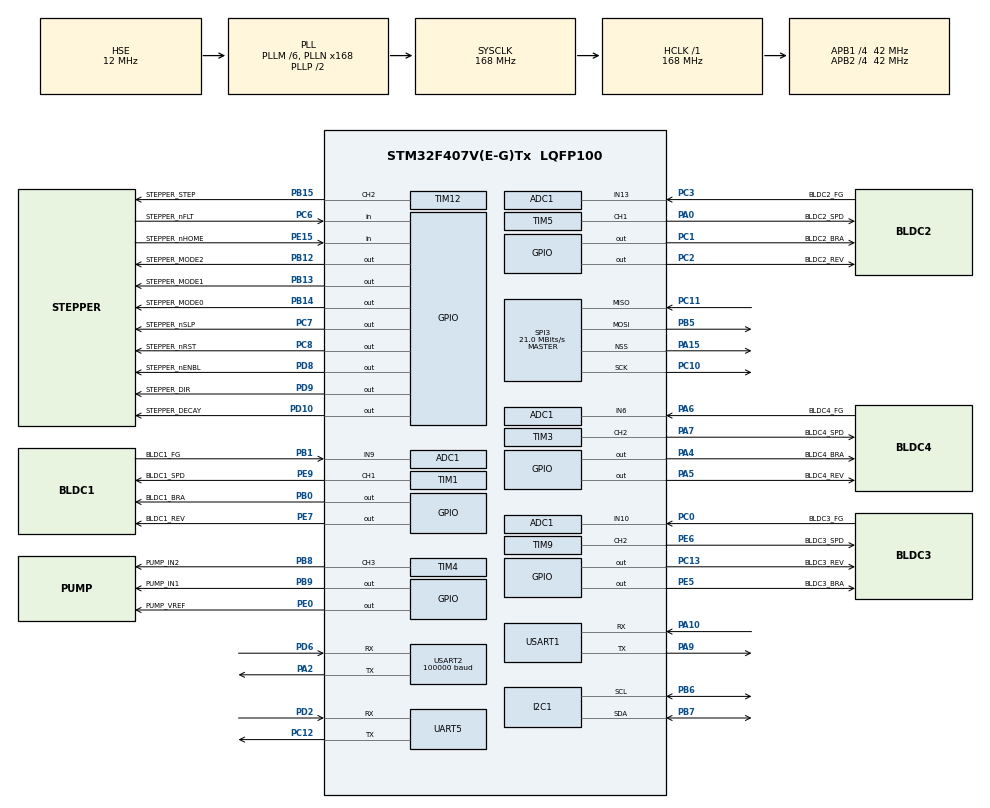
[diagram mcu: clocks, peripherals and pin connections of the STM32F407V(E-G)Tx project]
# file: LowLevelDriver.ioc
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ADC1.Channel-1\#ChannelRegularConversion=ADC_CHANNEL_9
ADC1.Channel-2\#ChannelRegularConversion=ADC_CHANNEL_6
ADC1.Channel-3\#ChannelRegularConversion=ADC_CHANNEL_10
ADC1.Channel-4\#ChannelRegularConversion=ADC_CHANNEL_13
ADC1.ClockPrescaler=ADC_CLOCK_SYNC_PCLK_DIV6
ADC1.ContinuousConvMode=ENABLE
ADC1.DMAContinuousRequests=ENABLE
ADC1.EOCSelection=ADC_EOC_SEQ_CONV
ADC1.NbrOfConversion=4
ADC1.NbrOfConversionFlag=1
ADC1.Rank-1\#ChannelRegularConversion=1
ADC1.Rank-2\#ChannelRegularConversion=2
ADC1.Rank-3\#ChannelRegularConversion=3
ADC1.Rank-4\#ChannelRegularConversion=4
ADC1.SamplingTime-1\#ChannelRegularConversion=ADC_SAMPLETIME_56CYCLES
ADC1.SamplingTime-2\#ChannelRegularConversion=ADC_SAMPLETIME_56CYCLES
ADC1.SamplingTime-3\#ChannelRegularConversion=ADC_SAMPLETIME_56CYCLES
ADC1.SamplingTime-4\#ChannelRegularConversion=ADC_SAMPLETIME_56CYCLES
ADC1.ScanConvMode=ENABLE
ADC1.master=1
Dma.ADC1.0.Direction=DMA_PERIPH_TO_MEMORY
Dma.ADC1.0.FIFOMode=DMA_FIFOMODE_DISABLE
Dma.ADC1.0.Instance=DMA2_Stream0
Dma.ADC1.0.MemDataAlignment=DMA_MDATAALIGN_HALFWORD
Dma.ADC1.0.MemInc=DMA_MINC_ENABLE
Dma.ADC1.0.Mode=DMA_CIRCULAR
Dma.ADC1.0.PeriphDataAlignment=DMA_PDATAALIGN_HALFWORD
Dma.ADC1.0.PeriphInc=DMA_PINC_DISABLE
Dma.ADC1.0.Priority=DMA_PRIORITY_LOW
Dma.Request0=ADC1
Dma.Request1=USART2_RX
Dma.USART2_RX.1.Direction=DMA_PERIPH_TO_MEMORY
Dma.USART2_RX.1.FIFOMode=DMA_FIFOMODE_DISABLE
Dma.USART2_RX.1.Instance=DMA1_Stream5
Dma.USART2_RX.1.MemDataAlignment=DMA_MDATAALIGN_BYTE
Dma.USART2_RX.1.MemInc=DMA_MINC_ENABLE
Dma.USART2_RX.1.Mode=DMA_NORMAL
Dma.USART2_RX.1.PeriphDataAlignment=DMA_PDATAALIGN_BYTE
Dma.USART2_RX.1.PeriphInc=DMA_PINC_DISABLE
Dma.USART2_RX.1.Priority=DMA_PRIORITY_LOW
FREERTOS.Tasks01=defaultTask,0,128,StartDefaultTask,Default,NULL,Dynamic,NULL,NULL
FREERTOS.configENABLE_FPU=1
Mcu.Family=STM32F4
Mcu.Name=STM32F407V(E-G)Tx
Mcu.Package=LQFP100
NVIC.DMA1_Stream5_IRQn=true\:5\:0\:false\:false\:true\:true\:false\:true\:true
NVIC.DMA2_Stream0_IRQn=true\:5\:0\:false\:false\:true\:true\:false\:true\:true
NVIC.PriorityGroup=NVIC_PRIORITYGROUP_4
NVIC.TIM6_DAC_IRQn=true\:15\:0\:false\:false\:true\:false\:false\:true\:true
NVIC.TimeBase=TIM6_DAC_IRQn
NVIC.TimeBaseIP=TIM6
PA0-WKUP.GPIO_Label=BLDC2_SPD
PA0-WKUP.Signal=S_TIM5_CH1
PA10.Mode=Asynchronous
PA10.Signal=USART1_RX
PA13.Mode=Serial_Wire
PA13.Signal=SYS_JTMS-SWDIO
PA14.Mode=Serial_Wire
PA14.Signal=SYS_JTCK-SWCLK
PA15.Mode=NSS_Signal_Hard_Output
PA15.Signal=SPI3_NSS
PA2.Mode=Asynchronous
PA2.Signal=USART2_TX
PA4.GPIO_Label=BLDC4_BRA
PA4.Signal=GPIO_Output
PA5.GPIO_Label=BLDC4_REV
PA5.Signal=GPIO_Output
PA6.GPIO_Label=BLDC4_FG
PA6.Signal=ADCx_IN6
PA7.GPIO_Label=BLDC4_SPD
PA7.Signal=S_TIM3_CH2
PA9.Mode=Asynchronous
PA9.Signal=USART1_TX
PB0.GPIO_Label=BLDC1_BRA
PB0.Signal=GPIO_Output
PB1.GPIO_Label=BLDC1_FG
PB1.Signal=ADCx_IN9
PB12.GPIO_Label=STEPPER_MODE2
PB12.Signal=GPIO_Output
PB13.GPIO_Label=STEPPER_MODE1
PB13.Signal=GPIO_Output
PB14.GPIO_Label=STEPPER_MODE0
PB14.Signal=GPIO_Output
PB15.GPIO_Label=STEPPER_STEP
PB15.Signal=S_TIM12_CH2
PB5.Mode=Full_Duplex_Master
PB5.Signal=SPI3_MOSI
PB6.Mode=I2C
PB6.Signal=I2C1_SCL
PB7.Mode=I2C
PB7.Signal=I2C1_SDA
PB8.GPIO_Label=PUMP_IN2
PB8.Signal=S_TIM4_CH3
PB9.GPIO_Label=PUMP_IN1
PB9.PinState=GPIO_PIN_SET
PB9.Signal=GPIO_Output
PC0.GPIO_Label=BLDC3_FG
PC0.Signal=ADCx_IN10
PC1.GPIO_Label=BLDC2_BRA
PC1.Signal=GPIO_Output
PC10.Mode=Full_Duplex_Master
PC10.Signal=SPI3_SCK
PC11.Mode=Full_Duplex_Master
PC11.Signal=SPI3_MISO
PC12.Mode=Asynchronous
PC12.Signal=UART5_TX
PC13-ANTI_TAMP.GPIO_Label=BLDC3_REV
PC13-ANTI_TAMP.Signal=GPIO_Output
PC2.GPIO_Label=BLDC2_REV
PC2.Signal=GPIO_Output
PC3.GPIO_Label=BLDC2_FG
PC3.Signal=ADCx_IN13
PC6.GPIO_Label=STEPPER_nFLT
PC6.GPIO_PuPd=GPIO_PULLUP
PC6.Signal=GPIO_Input
PC7.GPIO_Label=STEPPER_nSLP
PC7.PinState=GPIO_PIN_SET
PC7.Signal=GPIO_Output
PC8.GPIO_Label=STEPPER_nRST
PC8.Signal=GPIO_Output
PD10.GPIO_Label=STEPPER_DECAY
PD10.Signal=GPIO_Output
PD2.Mode=Asynchronous
PD2.Signal=UART5_RX
PD6.Mode=Asynchronous
PD6.Signal=USART2_RX
PD8.GPIO_Label=STEPPER_nENBL
PD8.Signal=GPIO_Output
PD9.GPIO_Label=STEPPER_DIR
PD9.Signal=GPIO_Output
PE0.GPIO_Label=PUMP_VREF
PE0.PinState=GPIO_PIN_SET
PE0.Signal=GPIO_Output
PE15.GPIO_Label=STEPPER_nHOME
PE15.GPIO_PuPd=GPIO_PULLUP
PE15.Signal=GPIO_Input
PE5.GPIO_Label=BLDC3_BRA
PE5.Signal=GPIO_Output
PE6.GPIO_Label=BLDC3_SPD
PE6.Signal=S_TIM9_CH2
PE7.GPIO_Label=BLDC1_REV
PE7.Signal=GPIO_Output
PE9.GPIO_Label=BLDC1_SPD
PE9.Signal=S_TIM1_CH1
PH0-OSC_IN.Mode=HSE-External-Oscillator
PH0-OSC_IN.Signal=RCC_OSC_IN
PH1-OSC_OUT.Mode=HSE-External-Oscillator
PH1-OSC_OUT.Signal=RCC_OSC_OUT
ProjectManager.HeapSize=0x200
ProjectManager.StackSize=0x400
ProjectManager.TargetToolchain=MDK-ARM V5.32
RCC.48MHZClocksFreq_Value=48000000
RCC.AHBFreq_Value=168000000
RCC.APB1CLKDivider=RCC_HCLK_DIV4
RCC.APB1Freq_Value=42000000
RCC.APB1TimFreq_Value=84000000
RCC.APB2CLKDivider=RCC_HCLK_DIV4
RCC.APB2Freq_Value=42000000
RCC.APB2TimFreq_Value=84000000
RCC.CortexFreq_Value=168000000
RCC.HCLKFreq_Value=168000000
RCC.HSE_VALUE=12000000
RCC.HSI_VALUE=16000000
RCC.LSE_VALUE=32768
RCC.PLLM=6
RCC.PLLN=168
RCC.PLLQ=7
RCC.PLLSourceVirtual=RCC_PLLSOURCE_HSE
RCC.SYSCLKFreq_VALUE=168000000
RCC.SYSCLKSource=RCC_SYSCLKSOURCE_PLLCLK
RCC.VCOOutputFreq_Value=336000000
SH.ADCx_IN10.0=ADC1_IN10,IN10
SH.ADCx_IN13.0=ADC1_IN13,IN13
SH.ADCx_IN6.0=ADC1_IN6,IN6
SH.ADCx_IN9.0=ADC1_IN9,IN9
SH.S_TIM12_CH2.0=TIM12_CH2,PWM Generation2 CH2
SH.S_TIM1_CH1.0=TIM1_CH1,PWM Generation1 CH1
SH.S_TIM3_CH2.0=TIM3_CH2,PWM Generation2 CH2
SH.S_TIM4_CH3.0=TIM4_CH3,PWM Generation3 CH3
SH.S_TIM5_CH1.0=TIM5_CH1,PWM Generation1 CH1
SH.S_TIM9_CH2.0=TIM9_CH2,PWM Generation2 CH2
SPI3.BaudRatePrescaler=SPI_BAUDRATEPRESCALER_2
SPI3.CalculateBaudRate=21.0 MBits/s
SPI3.Direction=SPI_DIRECTION_2LINES
SPI3.Mode=SPI_MODE_MASTER
SPI3.VirtualNSS=VM_NSSHARD
SPI3.VirtualType=VM_MASTER
TIM1.Channel-PWM\ Generation1\ CH1=TIM_CHANNEL_1
TIM1.OCPolarity_1=TIM_OCPOLARITY_LOW
TIM1.Period=1000 - 1
TIM1.Prescaler=4 - 1
TIM12.Channel-PWM\ Generation2\ CH2=TIM_CHANNEL_2
TIM12.Period=400 - 1
TIM12.Prescaler=21 - 1
TIM12.Pulse-PWM\ Generation2\ CH2=200
TIM3.Channel-PWM\ Generation2\ CH2=TIM_CHANNEL_2
TIM3.OCPolarity_2=TIM_OCPOLARITY_LOW
TIM3.Period=1000 - 1
TIM3.Prescaler=4 - 1
TIM4.Channel-PWM\ Generation3\ CH3=TIM_CHANNEL_3
TIM4.OCPolarity_3=TIM_OCPOLARITY_LOW
TIM4.Period=1000 - 1
TIM4.Prescaler=4 - 1
TIM5.Channel-PWM\ Generation1\ CH1=TIM_CHANNEL_1
TIM5.OCPolarity_1=TIM_OCPOLARITY_LOW
TIM5.Period=1000 - 1
TIM5.Prescaler=4 - 1
TIM9.Channel-PWM\ Generation2\ CH2=TIM_CHANNEL_2
TIM9.OCPolarity_2=TIM_OCPOLARITY_LOW
TIM9.Period=1000 - 1
TIM9.Prescaler=4 - 1
UART5.VirtualMode=Asynchronous
USART1.VirtualMode=VM_ASYNC
USART2.BaudRate=100000
USART2.Mode=MODE_RX
USART2.Parity=PARITY_EVEN
USART2.StopBits=STOPBITS_2
USART2.VirtualMode=VM_ASYNC
USART2.WordLength=WORDLENGTH_9B
VP_FREERTOS_VS_CMSIS_V1.Mode=CMSIS_V1
VP_RNG_VS_RNG.Mode=RNG_Activate
VP_SYS_VS_tim6.Mode=TIM6
VP_TIM12_VS_ClockSourceINT.Mode=Internal
VP_TIM1_VS_ClockSourceINT.Mode=Internal
VP_TIM3_VS_ClockSourceINT.Mode=Internal
VP_TIM4_VS_ClockSourceINT.Mode=Internal
VP_TIM5_VS_ClockSourceINT.Mode=Internal
VP_TIM9_VS_ClockSourceINT.Mode=Internal
board=custom

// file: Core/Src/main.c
/* USER CODE BEGIN Header */
/**
  ******************************************************************************
  * @file           : main.c
  * @brief          : Main program body
  ******************************************************************************
  * @attention
  *
  * Copyright (c) 2025 STMicroelectronics.
  * All rights reserved.
  *
  * This software is licensed under terms that can be found in the LICENSE file
  * in the root directory of this software component.
  * If no LICENSE file comes with this software, it is provided AS-IS.
  *
  ******************************************************************************
  */
/* USER CODE END Header */
#include "main.h"
#include "cmsis_os.h"
#include "adc.h"
#include "dma.h"
#include "i2c.h"
#include "rng.h"
#include "spi.h"
#include "tim.h"
#include "usart.h"
#include "gpio.h"

void SystemClock_Config(void);
void MX_FREERTOS_Init(void);

int main(void)
{

  /* MCU Configuration--------------------------------------------------------*/

  /* Reset of all peripherals, Initializes the Flash interface and the Systick. */
  HAL_Init();

  /* Configure the system clock */
  SystemClock_Config();

  /* Initialize all configured peripherals */
  MX_GPIO_Init();
  MX_DMA_Init();
  MX_ADC1_Init();
  MX_TIM1_Init();
  MX_TIM3_Init();
  MX_TIM4_Init();
  MX_TIM5_Init();
  MX_TIM9_Init();
  MX_TIM12_Init();
  MX_I2C1_Init();
  MX_RNG_Init();
  MX_SPI3_Init();
  MX_UART5_Init();
  MX_USART1_UART_Init();
  MX_USART2_UART_Init();

  /* Call init function for freertos objects (in cmsis_os2.c) */
  MX_FREERTOS_Init();

  /* Start scheduler */
  osKernelStart();

  /* We should never get here as control is now taken by the scheduler */

  /* Infinite loop */
  while (1)
  {

  }
}

void SystemClock_Config(void)
{
  RCC_OscInitTypeDef RCC_OscInitStruct = {0};
  RCC_ClkInitTypeDef RCC_ClkInitStruct = {0};

  /** Configure the main internal regulator output voltage
  */
  __HAL_RCC_PWR_CLK_ENABLE();
  __HAL_PWR_VOLTAGESCALING_CONFIG(PWR_REGULATOR_VOLTAGE_SCALE1);

  /** Initializes the RCC Oscillators according to the specified parameters
  * in the RCC_OscInitTypeDef structure.
  */
  RCC_OscInitStruct.OscillatorType = RCC_OSCILLATORTYPE_HSE;
  RCC_OscInitStruct.HSEState = RCC_HSE_ON;
  RCC_OscInitStruct.PLL.PLLState = RCC_PLL_ON;
  RCC_OscInitStruct.PLL.PLLSource = RCC_PLLSOURCE_HSE;
  RCC_OscInitStruct.PLL.PLLM = 6;
  RCC_OscInitStruct.PLL.PLLN = 168;
  RCC_OscInitStruct.PLL.PLLP = RCC_PLLP_DIV2;
  RCC_OscInitStruct.PLL.PLLQ = 7;
  if (HAL_RCC_OscConfig(&RCC_OscInitStruct) != HAL_OK)
  {
    Error_Handler();
  }

  /** Initializes the CPU, AHB and APB buses clocks
  */
  RCC_ClkInitStruct.ClockType = RCC_CLOCKTYPE_HCLK|RCC_CLOCKTYPE_SYSCLK
                              |RCC_CLOCKTYPE_PCLK1|RCC_CLOCKTYPE_PCLK2;
  RCC_ClkInitStruct.SYSCLKSource = RCC_SYSCLKSOURCE_PLLCLK;
  RCC_ClkInitStruct.AHBCLKDivider = RCC_SYSCLK_DIV1;
  RCC_ClkInitStruct.APB1CLKDivider = RCC_HCLK_DIV4;
  RCC_ClkInitStruct.APB2CLKDivider = RCC_HCLK_DIV4;

  if (HAL_RCC_ClockConfig(&RCC_ClkInitStruct, FLASH_LATENCY_5) != HAL_OK)
  {
    Error_Handler();
  }
}

void HAL_TIM_PeriodElapsedCallback(TIM_HandleTypeDef *htim)
{
  if (htim->Instance == TIM6) {
    HAL_IncTick();
  }
}

void Error_Handler(void)
{
  __disable_irq();
  while (1)
  {
  }
}

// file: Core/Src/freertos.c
/* USER CODE BEGIN Header */
/**
  ******************************************************************************
  * File Name          : freertos.c
  * Description        : Code for freertos applications
  ******************************************************************************
  * @attention
  *
  * Copyright (c) 2025 STMicroelectronics.
  * All rights reserved.
  *
  * This software is licensed under terms that can be found in the LICENSE file
  * in the root directory of this software component.
  * If no LICENSE file comes with this software, it is provided AS-IS.
  *
  ******************************************************************************
  */
/* USER CODE END Header */

#include "FreeRTOS.h"
#include "task.h"
#include "main.h"
#include "cmsis_os.h"

/* USER CODE BEGIN Includes */
#include "test_task.h"
/* USER CODE END Includes */

osThreadId defaultTaskHandle;

//void StartDefaultTask(void const * argument);

void MX_FREERTOS_Init(void); /* (MISRA C 2004 rule 8.1) */

/* GetIdleTaskMemory prototype (linked to static allocation support) */
void vApplicationGetIdleTaskMemory( StaticTask_t **ppxIdleTaskTCBBuffer, StackType_t **ppxIdleTaskStackBuffer, uint32_t *pulIdleTaskStackSize );

/* USER CODE BEGIN GET_IDLE_TASK_MEMORY */
static StaticTask_t xIdleTaskTCBBuffer;
static StackType_t xIdleStack[configMINIMAL_STACK_SIZE];

void vApplicationGetIdleTaskMemory( StaticTask_t **ppxIdleTaskTCBBuffer, StackType_t **ppxIdleTaskStackBuffer, uint32_t *pulIdleTaskStackSize )
{
  *ppxIdleTaskTCBBuffer = &xIdleTaskTCBBuffer;
  *ppxIdleTaskStackBuffer = &xIdleStack[0];
  *pulIdleTaskStackSize = configMINIMAL_STACK_SIZE;
  /* place for user code */
}
/* USER CODE END GET_IDLE_TASK_MEMORY */

void MX_FREERTOS_Init(void) {

  /* Create the thread(s) */
  /* definition and creation of defaultTask */
//  osThreadDef(defaultTask, StartDefaultTask, osPriorityNormal, 0, 128);
//  defaultTaskHandle = osThreadCreate(osThread(defaultTask), NULL);

  /* USER CODE BEGIN RTOS_THREADS */
  /* add threads, ... */
  xTaskCreate(Task1, "TestTask1", 128, NULL, 0, NULL);
  xTaskCreate(RemoteTask, "TestTask2", 128, NULL, 0, NULL);
  /* USER CODE END RTOS_THREADS */

}

//void StartDefaultTask(void const * argument)
//{
//  /* USER CODE BEGIN StartDefaultTask */
//  /* Infinite loop */
//  for(;;)
//  {
//    osDelay(1);
//  }
//  /* USER CODE END StartDefaultTask */
//}
